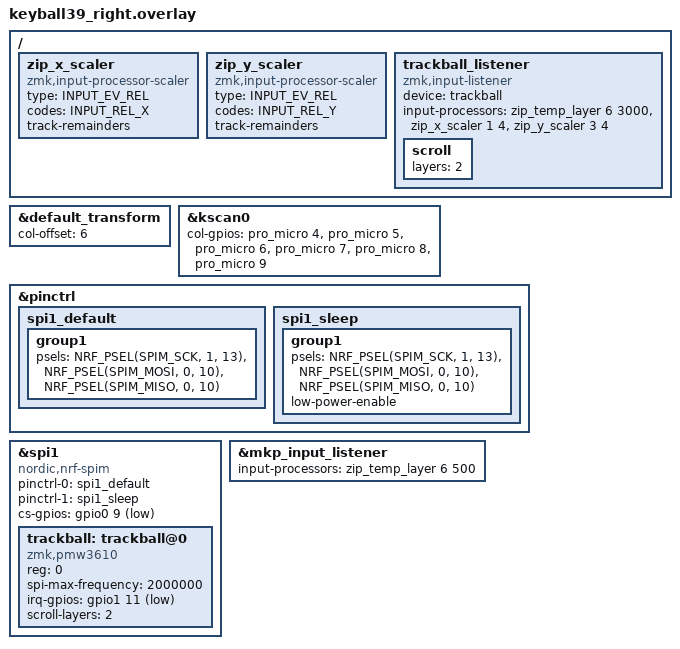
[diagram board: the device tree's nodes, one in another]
/*
 * Copyright (c) 2020 ZMK Contributors
 *
 * SPDX-License-Identifier: MIT
 */

#include <zephyr/dt-bindings/input/input-event-codes.h>
#include <behaviors.dtsi>
#include <input/processors.dtsi>

#include "keyball39.dtsi"

/*
 * !! LAYER INDICES ARE HARD-CODED IN THIS FILE !!
 *
 * `scroll-layers`, `layers` and `&zip_temp_layer` below take raw layer numbers.
 * This overlay is not preprocessed together with the keymap, so the readable
 * NAV / MOUSE macros from config/base.keymap are NOT available here.
 *
 * Current mapping (see the #define block at the top of config/base.keymap):
 *     DEF 0   PLAIN 1   NAV 2   FN 3   NUM 4   SYS 5   MOUSE 6   TOTP 7
 *
 * The numbers used here are NAV = 2 and MOUSE = 6. If a layer is ever added,
 * removed or reordered, these do NOT break the build -- they silently point at
 * the wrong layer. Symptoms: rolling the ball scrolls on the wrong layer, or
 * auto-mouse activates something other than the Mouse layer. Grep this file
 * for numeric layer values whenever the keymap's layer list changes.
 */

&default_transform {
    col-offset = <6>;
};

&kscan0 {
	col-gpios
		= <&pro_micro 4 GPIO_ACTIVE_HIGH>
		, <&pro_micro 5 GPIO_ACTIVE_HIGH>
		, <&pro_micro 6 GPIO_ACTIVE_HIGH>
		, <&pro_micro 7 GPIO_ACTIVE_HIGH>
		, <&pro_micro 8 GPIO_ACTIVE_HIGH>
        , <&pro_micro 9 GPIO_ACTIVE_HIGH>
		;
};

&pinctrl {
    spi1_default: spi1_default {
        group1 {
            psels = <NRF_PSEL(SPIM_SCK, 1, 13)>,
                <NRF_PSEL(SPIM_MOSI, 0, 10)>,
                <NRF_PSEL(SPIM_MISO, 0, 10)>;
        };
    };

    spi1_sleep: spi1_sleep {
        group1 {
            psels = <NRF_PSEL(SPIM_SCK, 1, 13)>,
                <NRF_PSEL(SPIM_MOSI, 0, 10)>,
                <NRF_PSEL(SPIM_MISO, 0, 10)>;
            low-power-enable;
        };
    };
};

&spi1 {
    status = "okay";
    compatible = "nordic,nrf-spim";
    pinctrl-0 = <&spi1_default>;
    pinctrl-1 = <&spi1_sleep>;
    pinctrl-names = "default", "sleep";
    cs-gpios = <&gpio0 9 GPIO_ACTIVE_LOW>;

    // Community PMW3610 driver (mochukeeb/zmk-pmw3610-driver, pinned in
    // config/west.yml) — the exact driver + settings used by the reference
    // Keyball39 config whose trackball tracks correctly. All sensor tuning
    // (CPI, CPI divisor, orientation, smart algorithm, polling rate,
    // downshift/rest timings, scroll direction) lives in keyball39_right.conf
    // as CONFIG_PMW3610_* — this driver takes its knobs from Kconfig, not DT
    // properties (the native pixart,pmw3610 driver was the opposite). The
    // hardware wiring (SPI pins, CS on gpio0 9, motion IRQ on gpio1 11) is
    // identical to the native-driver setup; only the `compatible` and the
    // IRQ property name (`irq-gpios`, not `motion-gpios`) differ.
    trackball: trackball@0 {
        status = "okay";
        compatible = "zmk,pmw3610";
        reg = <0>;
        spi-max-frequency = <2000000>;
        irq-gpios = <&gpio1 11 (GPIO_ACTIVE_LOW | GPIO_PULL_UP)>;
        // Scroll on the Nav layer (index 2): while LH1 (&lt_spc NAV 0) is held
        // the driver emits wheel events instead of cursor motion, so rolling
        // the ball scrolls. Matches the pre-existing scroll-on-Nav behavior.
        // (No `snipe-layers`/`arrows` — those map to layers the reference
        // keymap has but this one doesn't. No `automouse-layer` — auto-mouse
        // is handled by &zip_temp_layer in the listener below; see west.yml
        // for why the driver's built-in automouse can't compile on ZMK main.)
        scroll-layers = <2>;
    };
};

// Each &mkp press (LCLK/MCLK/RCLK on the Mouse layer) re-arms the Mouse
// layer's deactivation timer to 500 ms, so a multi-click (double-/triple-
// click) keeps the layer alive and it deactivates 500 ms after the last
// click — comfortably inside the OS double-click window (250–500 ms).
// `zip_temp_layer` keys its disable work on the layer index and reschedules
// on each event, so this 500 ms schedule and the trackball listener's
// 3000 ms one below don't conflict; whichever fires latest wins.
&mkp_input_listener {
    input-processors = <&zip_temp_layer 6 500>;
};

/ {
    // Per-axis cursor scaling. The driver emits full-resolution raw counts
    // (CONFIG_PMW3610_CPI_DIVIDOR=1), and we scale here with track-remainders
    // so the fraction dropped by integer division is carried into the next
    // event instead of being rounded away — that's what keeps slow motion
    // smooth instead of stepping. (Letting the driver do the ÷4 is what made
    // vertical notchy: its integer division has no remainder tracking, and the
    // coarse result was then tripled.)
    //
    //   X: ×1/4  → effective ~300 CPI (1200/4), matches the previous feel.
    //   Y: ×3/4  → 3× the per-count gain of X, correcting this unit's ~3×
    //              weaker vertical sensor response. Net vertical speed equals
    //              horizontal, now at full 1-count granularity.
    //
    // To rebalance the axes later, change only the Y ratio (3/4). Each scaler
    // filters on `codes`, so zip_x_scaler ignores Y (and vice versa) and both
    // ignore scroll wheel events.
    zip_x_scaler: zip_x_scaler {
        compatible = "zmk,input-processor-scaler";
        #input-processor-cells = <2>;
        type = <INPUT_EV_REL>;
        codes = <INPUT_REL_X>;
        track-remainders;
    };

    zip_y_scaler: zip_y_scaler {
        compatible = "zmk,input-processor-scaler";
        #input-processor-cells = <2>;
        type = <INPUT_EV_REL>;
        codes = <INPUT_REL_Y>;
        track-remainders;
    };

    trackball_listener: trackball_listener {
        compatible = "zmk,input-listener";
        device = <&trackball>;
        // Auto-mouse: any cursor-motion event (REL_X/REL_Y — the community
        // driver emits these in its default MOVE mode) activates the Mouse
        // layer (index 6) for 3000 ms, turning the right-hand/thumb keys into
        // mouse buttons after you touch the ball. Auto-deactivates 3 s after
        // the last motion (or 500 ms after the last click, via
        // &mkp_input_listener above). Overall speed + the X/Y rebalance are set
        // by the per-axis scalers above.
        input-processors = <&zip_temp_layer 6 3000 &zip_x_scaler 1 4 &zip_y_scaler 3 4>;

        // Nav layer (index 2) = scroll. The sensor node already remaps motion
        // to wheel events on this layer (scroll-layers = <2>), so this override
        // REPLACES the auto-mouse chain with nothing: an empty processor list
        // plus process-next defaulting to false means the base chain is skipped
        // (see input_listener.c:filter_with_input_config — a matched override
        // returns before apply_config(base)). Without it the wheel events would
        // trip &zip_temp_layer, flip on the Mouse layer, and the driver —
        // seeing Mouse (6) as the highest active layer rather than Nav (2) —
        // would revert to cursor mode mid-scroll.
        scroll {
            layers = <2>;
        };
    };
};
